# PIC32MZ1025DAA176 device description
Architecture: MIPS; Family: PIC32MZDA; Series: PIC32MZ
Registers are 32-bit, read-write, no defined reset value unless marked. A register's access mark holds for its fields unless they carry their own. Offsets are from the block's base; [hi:lo] are bit positions; {n}, {i} and the like mark numbered series.

## PCACHE
Instances: PCACHE 0x1f8e0000 in periph_indep
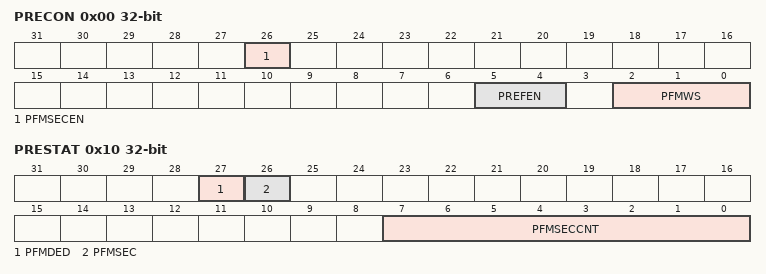
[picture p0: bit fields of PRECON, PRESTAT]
0x00 PRECON — Prefetch Module Control Register
  [26] PFMSECEN — Flash SEC Interrupt Enable bit
    1=Generate an interrupt when the PFMSEC bit (PRESTAT) is set; 0=Do not generate an interrupt when the PFMSEC bit is set
  [5:4] PREFEN — Predictive Prefetch Enable bits
    3=Enable predictive prefetch for any address; 2=Enable predictive prefetch for CPU instructions and CPU data; 1=Enable predictive prefetch for CPU instructions only; 0=Disable predictive prefetch
  [2:0] PFMWS — PFM Access Time Defined in Terms of SYSCLK Wait States bits
    7=Seven Wait states; 6=Six Wait states; 5=Five Wait states; 4=Four Wait states; 3=Three Wait states; 2=Two Wait states; 1=One Wait state; 0=Zero Wait states
0x10 PRESTAT — Prefetch Module Status Register
  [27] PFMDED — Flash Double-bit Error Detected Status bit
    1=A DED error has occurred; 0=A DED error has not occurred
  [26] PFMSEC — Flash Single-bit Error Corrected Status bit
    1=A SEC error occurred when PFMSECCNT was equal to zero; 0=A SEC error has not occurred
  [7:0] PFMSECCNT — Flash SEC Count bits
    255=SEC count of 255; 254=SEC count of 254; 1=SEC count of 1; 0=SEC count of 0

## RNG
Instances: RNG 0x1f8e6000 in periph_indep
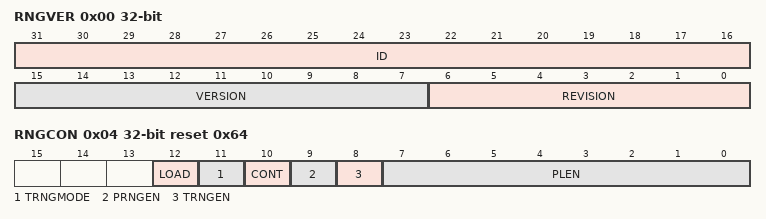
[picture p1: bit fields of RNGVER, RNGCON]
0x00 RNGVER ro — Random Number Generator Version Register
  [31:16] ID, [15:7] VERSION, [6:0] REVISION
0x04 RNGCON reset 0x64 — Random Number Generator Control Register
  [12] LOAD
  [11] TRNGMODE — TRNG Mode Selection bit
    1=Use ring oscillators with bias corrector; 0=Use ring oscillators with XOR tree
  [10] CONT — PRNG Number Shift Enable bit
    1=The PRNG random number is shifted every cycle; 0=The PRNG random number is shifted when the previous value is removed
  [9] PRNGEN — PRNG Operation Enable bit
    1=PRNG operation is enabled; 0=PRNG operation is not enabled
  [8] TRNGEN — TRNG Operation Enable bit
    1=TRNG operation is enabled; 0=TRNG operation is not enabled
  [7:0] PLEN — PRNG Polynomial Length bits
0x08 RNGPOLY1 reset 0xFFFF0000 — Random Number Generator Polynomial Register x (x = 1 or 2
  [31:0] POLY
0x0C RNGPOLY2 reset 0xFFFF0000 — Random Number Generator Polynomial Register x (x = 1 or 2)
  [31:0] POLY
0x10 RNGNUMGEN1 reset 0xFFFFFFFF — Random Number Generator Register x (x = 1 or 2)
  [31:0] RNG
0x14 RNGNUMGEN2 reset 0xFFFFFFFF — Random Number Generator Register x (x = 1 or 2)
  [31:0] RNG
0x18 RNGSEED1 ro — True Random Number Generator Seed Register x (x = 1 or 2
  [31:0] SEED
0x1C RNGSEED2 ro — True Random Number Generator Seed Register x (x = 1 or 2
  [31:0] SEED
0x20 RNGCNT — True Random Number Generator Count Register
  [6:0] RCNT

## RPIN
Instances: RPIN 0x1f801404 in periph_pb1_std
0x00 INT1R
  [3:0] INT1R
0x04 INT2R
  [3:0] INT2R
0x08 INT3R
  [3:0] INT3R
0x0C INT4R
  [3:0] INT4R
{0xC+4i} T{i}CKR (i=2..9)
  [3:0] T{i}CKR
{0x30+4i} IC{i}R (i=1..9)
  [3:0] IC{i}R
0x5C OCFAR
  [3:0] OCFAR
{0x5C+8i} U{i}RXR (i=1..6)
  [3:0] U{i}RXR
{0x60+8i} U{i}CTSR (i=1..6)
  [3:0] U{i}CTSR
{0x8C+0xC*i} SDI{i}R (i=1..6)
  [3:0] SDI{i}R
{0x90+0xC*i} SS{i}R (i=1..6)
  [3:0] SS{i}R
0xDC C1RXR
  [3:0] C1RXR
0xE0 C2RXR
  [3:0] C2RXR
0xE4 REFCLKI1R
  [3:0] REFCLKI1R
0xEC REFCLKI3R
  [3:0] REFCLKI3R
0xF0 REFCLKI4R
  [3:0] REFCLKI4R

## RPOUT
Instances: RPOUT 0x1f801538 in periph_pb1_std
0x00 RPA14R
  [3:0] RPA14R
0x04 RPA15R
  [3:0] RPA15R
{0x8+4i} RPB{i}R (i=0..3)
  [3:0] RPB{i}R
{0x8+4i} RPB{i}R (i=5..10)
  [3:0] RPB{i}R
0x40 RPB14R
  [3:0] RPB14R
0x44 RPB15R
  [3:0] RPB15R
{0x48+4i} RPC{i}R (i=1..4)
  [3:0] RPC{i}R
0x7C RPC13R
  [3:0] RPC13R
0x80 RPC14R
  [3:0] RPC14R
{0x88+4i} RPD{i}R (i=0..7)
  [3:0] RPD{i}R
{0x88+4i} RPD{i}R (i=9..12)
  [3:0] RPD{i}R
0xC0 RPD14R
  [3:0] RPD14R
0xC4 RPD15R
  [3:0] RPD15R
0xD4 RPE3R
  [3:0] RPE3R
0xDC RPE5R
  [3:0] RPE5R
0xE8 RPE8R
  [3:0] RPE8R
0xEC RPE9R
  [3:0] RPE9R
{0x108+4i} RPF{i}R (i=0..5)
  [3:0] RPF{i}R
0x128 RPF8R
  [3:0] RPF8R
0x138 RPF12R
  [3:0] RPF12R
0x13C RPF13R
  [3:0] RPF13R
0x148 RPG0R
  [3:0] RPG0R
0x14C RPG1R
  [3:0] RPG1R
{0x148+4i} RPG{i}R (i=6..9)
  [3:0] RPG{i}R

## Notices in the file
Copyright (c) 2017 Microchip Technology Inc.
SPDX-License-Identifier: Apache-2.0
Licensed under the Apache License, Version 2.0 (the "License");
you may not use this file except in compliance with the License.
You may obtain a copy of the License at
http://www.apache.org/licenses/LICENSE-2.0
Unless required by applicable law or agreed to in writing, software
distributed under the License is distributed on an "AS IS" BASIS,
WITHOUT WARRANTIES OR CONDITIONS OF ANY KIND, either express or implied.
See the License for the specific language governing permissions and
limitations under the License.
